# f28p55x_gpio_ctrl_regs register map
Vendor: Texas Instruments
Peripheral module from a debugger description file (folder C2000).
Address unit: 16 bits
Registers are 32-bit, read-write, no defined reset value unless marked. A register's access mark holds for its fields unless they carry their own. Offsets are as the file gives them; lines under a group give offsets from that group; [hi:lo] are bit positions; {n}, {i} and the like mark numbered series; 'fields as' and 'values as' point back to an identical list; <NAME> marks a mode.

## GPIO_CTRL_REGS — GPIO CTRL Registers
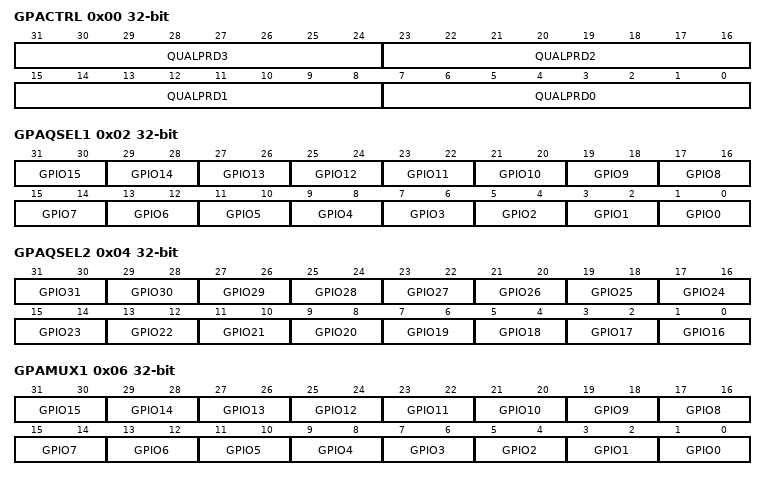
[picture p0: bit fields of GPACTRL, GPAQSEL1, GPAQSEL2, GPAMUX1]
0x00 GPACTRL — GPIO A Qualification Sampling Period Control (GPIO0 to 31)
  [8n+7:8n] QUALPRD{n} (n=0..3) — Qualification sampling period for GPIO{8n} to GPIO{8n+7}
0x02 GPAQSEL1 — GPIO A Qualifier Select 1 Register (GPIO0 to 15)
  [2n+1:2n] GPIO{n} (n=0..15) — Select input qualification type for GPIO{n}
0x04 GPAQSEL2 — GPIO A Qualifier Select 2 Register (GPIO16 to 31)
  [2n-31:2n-32] GPIO{n} (n=16..31) — Select input qualification type for GPIO{n}
0x06 GPAMUX1 — GPIO A Mux 1 Register (GPIO0 to 15)
  [2n+1:2n] GPIO{n} (n=0..15) — Defines pin-muxing selection for GPIO{n}
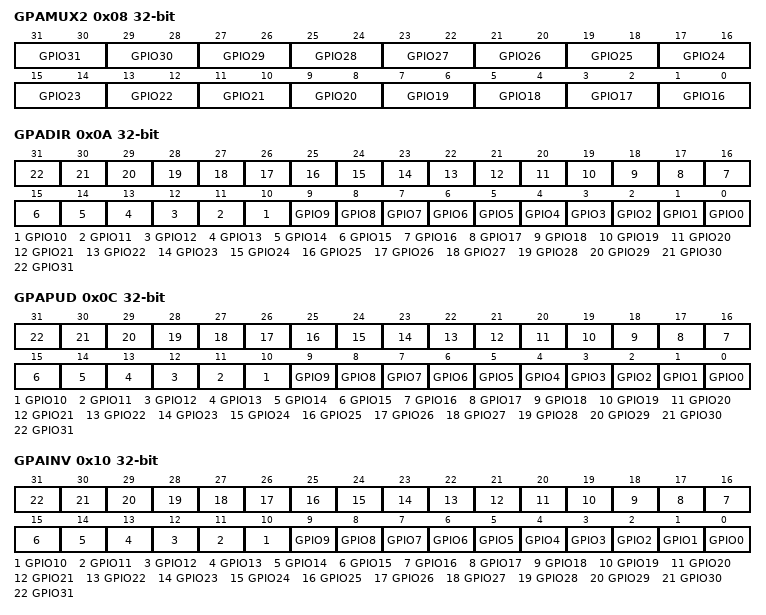
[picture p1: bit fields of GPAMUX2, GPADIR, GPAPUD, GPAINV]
0x08 GPAMUX2 — GPIO A Mux 2 Register (GPIO16 to 31)
  [2n-31:2n-32] GPIO{n} (n=16..31) — Defines pin-muxing selection for GPIO{n}
0x0A GPADIR — GPIO A Direction Register (GPIO0 to 31)
  [n] GPIO{n} (n=0..31) — Defines direction for this pin in GPIO mode
0x0C GPAPUD — GPIO A Pull Up Disable Register (GPIO0 to 31)
  [n] GPIO{n} (n=0..31) — Pull-Up Disable control for this pin
0x10 GPAINV — GPIO A Input Polarity Invert Registers (GPIO0 to 31)
  [n] GPIO{n} (n=0..31) — Input inversion control for this pin
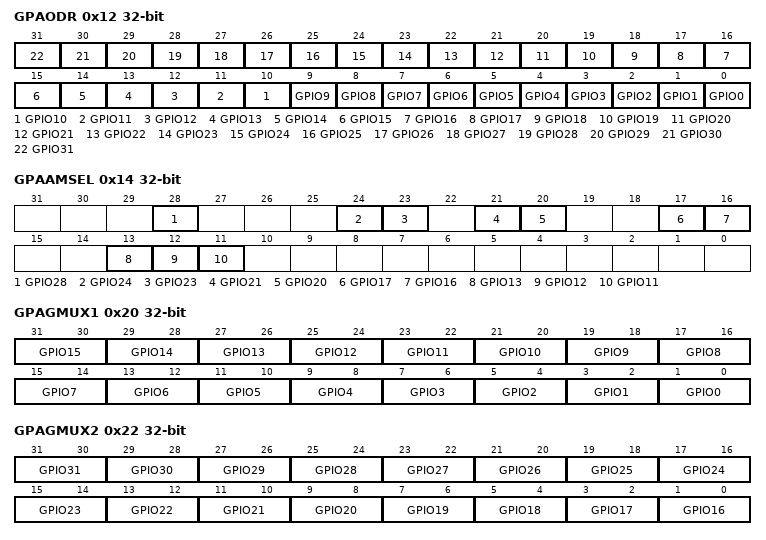
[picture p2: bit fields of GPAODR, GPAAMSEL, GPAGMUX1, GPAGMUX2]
0x12 GPAODR — GPIO A Open Drain Output Register (GPIO0 to GPIO31)
  [n] GPIO{n} (n=0..31) — Outpout Open-Drain control for this pin
0x14 GPAAMSEL — GPIO A Analog Mode Select register (GPIO0 to GPIO31)
  [28] GPIO28 — Analog Mode select for this pin
  [24] GPIO24 — Analog Mode select for this pin
  [23] GPIO23 — Analog Mode select for this pin
  [21] GPIO21 — Analog Mode select for this pin
  [20] GPIO20 — Analog Mode select for this pin
  [17] GPIO17 — Analog Mode select for this pin
  [16] GPIO16 — Analog Mode select for this pin
  [13] GPIO13 — Analog Mode select for this pin
  [12] GPIO12 — Analog Mode select for this pin
  [11] GPIO11 — Analog Mode select for this pin
0x20 GPAGMUX1 — GPIO A Peripheral Group Mux (GPIO0 to 15)
  fields as GPAMUX1
0x22 GPAGMUX2 — GPIO A Peripheral Group Mux (GPIO16 to 31)
  fields as GPAMUX2
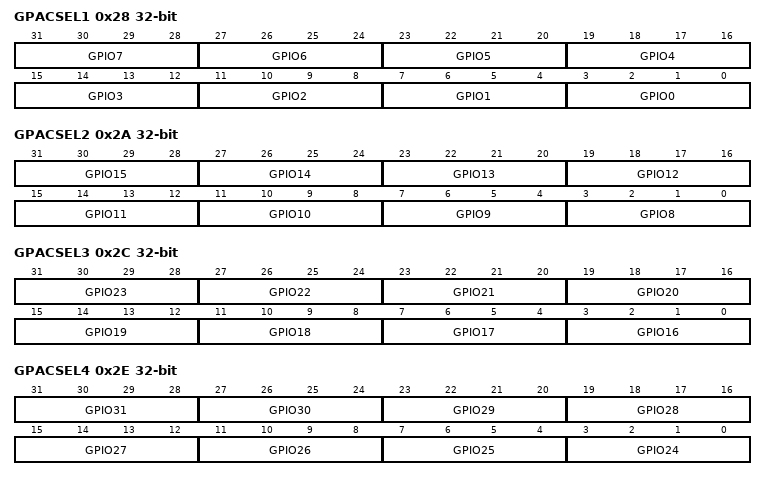
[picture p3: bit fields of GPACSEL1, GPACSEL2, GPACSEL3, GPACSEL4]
0x28 GPACSEL1 — GPIO A Core Select Register (GPIO0 to 7)
  [4n+3:4n] GPIO{n} (n=0..7) — GPIO{n} Controller CPU Select
0x2A GPACSEL2 — GPIO A Core Select Register (GPIO8 to 15)
  [4n-29:4n-32] GPIO{n} (n=8..15) — GPIO{n} Controller CPU Select
0x2C GPACSEL3 — GPIO A Core Select Register (GPIO16 to 23)
  [4n-61:4n-64] GPIO{n} (n=16..23) — GPIO{n} Controller CPU Select
0x2E GPACSEL4 — GPIO A Core Select Register (GPIO24 to 31)
  [4n-93:4n-96] GPIO{n} (n=24..31) — GPIO{n} Controller CPU Select
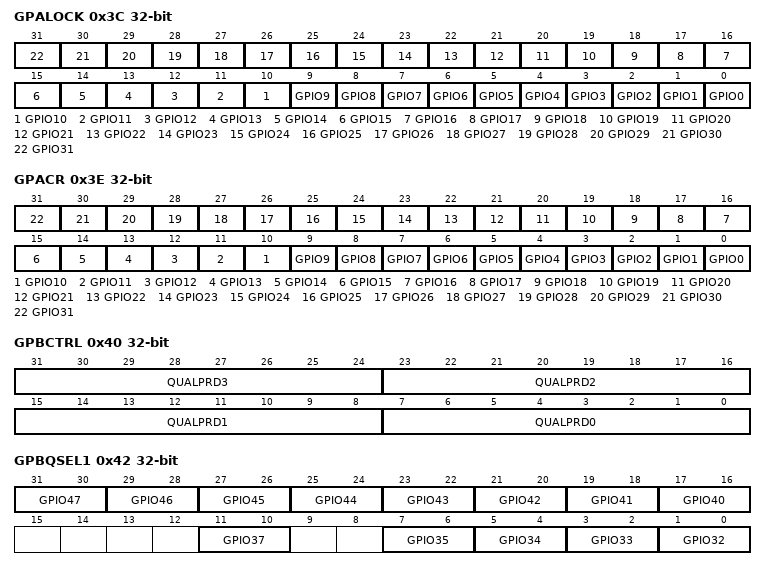
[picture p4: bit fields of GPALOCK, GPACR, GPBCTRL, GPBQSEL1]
0x3C GPALOCK — GPIO A Lock Configuration Register (GPIO0 to 31)
  [n] GPIO{n} (n=0..31) — Configuration Lock bit for this pin
0x3E GPACR — GPIO A Lock Commit Register (GPIO0 to 31)
  [n] GPIO{n} (n=0..31) — Configuration lock commit bit for this pin
0x40 GPBCTRL — GPIO B Qualification Sampling Period Control (GPIO32 to 63)
  [8n+7:8n] QUALPRD{n} (n=0..3) — Qualification sampling period for GPIO{8n+32} to GPIO{8n+39}
0x42 GPBQSEL1 — GPIO B Qualifier Select 1 Register (GPIO32 to 47)
  [2n-63:2n-64] GPIO{n} (n=40..47) — Select input qualification type for GPIO{n}
  [11:10] GPIO37 — Select input qualification type for GPIO37
  [2n-63:2n-64] GPIO{n} (n=32..35) — Select input qualification type for GPIO{n}
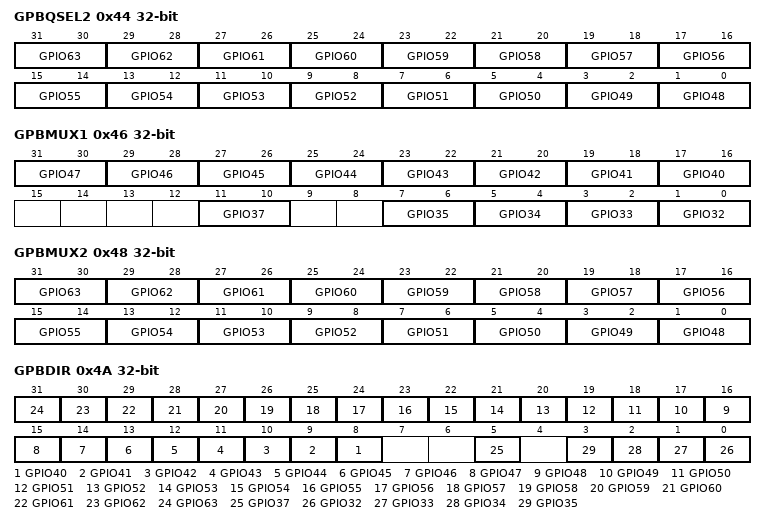
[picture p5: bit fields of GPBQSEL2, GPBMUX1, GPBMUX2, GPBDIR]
0x44 GPBQSEL2 — GPIO B Qualifier Select 2 Register (GPIO48 to 63)
  [2n-95:2n-96] GPIO{n} (n=48..63) — Select input qualification type for GPIO{n}
0x46 GPBMUX1 — GPIO B Mux 1 Register (GPIO32 to 47)
  [2n-63:2n-64] GPIO{n} (n=40..47) — Defines pin-muxing selection for GPIO{n}
  [11:10] GPIO37 — Defines pin-muxing selection for GPIO37
  [2n-63:2n-64] GPIO{n} (n=32..35) — Defines pin-muxing selection for GPIO{n}
0x48 GPBMUX2 — GPIO B Mux 2 Register (GPIO48 to 63)
  [2n-95:2n-96] GPIO{n} (n=48..63) — Defines pin-muxing selection for GPIO{n}
0x4A GPBDIR — GPIO B Direction Register (GPIO32 to 63)
  [n-32] GPIO{n} (n=40..63) — Defines direction for this pin in GPIO mode
  [5] GPIO37 — Defines direction for this pin in GPIO mode
  [n-32] GPIO{n} (n=32..35) — Defines direction for this pin in GPIO mode
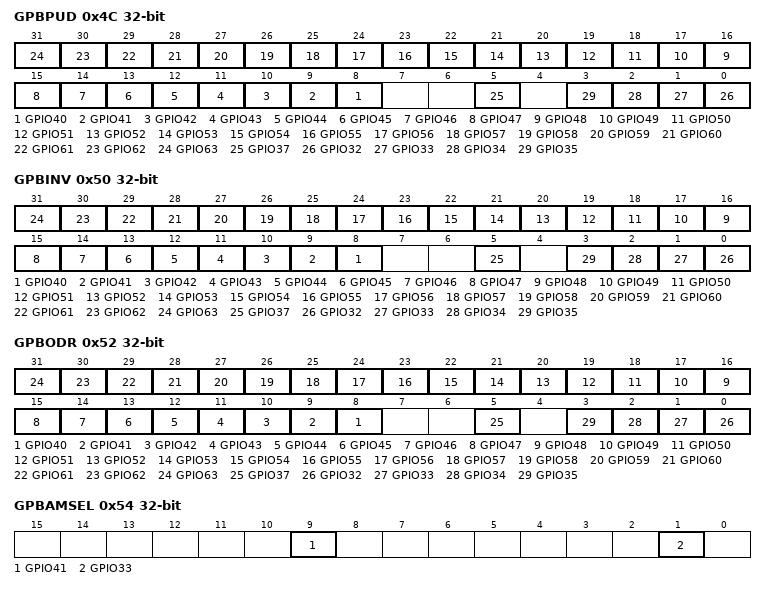
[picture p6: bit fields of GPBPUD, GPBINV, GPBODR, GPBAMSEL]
0x4C GPBPUD — GPIO B Pull Up Disable Register (GPIO32 to 63)
  [n-32] GPIO{n} (n=40..63) — Pull-Up Disable control for this pin
  [5] GPIO37 — Pull-Up Disable control for this pin
  [n-32] GPIO{n} (n=32..35) — Pull-Up Disable control for this pin
0x50 GPBINV — GPIO B Input Polarity Invert Registers (GPIO32 to 63)
  [n-32] GPIO{n} (n=40..63) — Input inversion control for this pin
  [5] GPIO37 — Input inversion control for this pin
  [n-32] GPIO{n} (n=32..35) — Input inversion control for this pin
0x52 GPBODR — GPIO B Open Drain Output Register (GPIO32 to GPIO63)
  [n-32] GPIO{n} (n=40..63) — Outpout Open-Drain control for this pin
  [5] GPIO37 — Outpout Open-Drain control for this pin
  [n-32] GPIO{n} (n=32..35) — Outpout Open-Drain control for this pin
0x54 GPBAMSEL — GPIO B Analog Mode Select register (GPIO32 to GPIO63)
  [9] GPIO41 — Analog Mode select for this pin
  [1] GPIO33 — Analog Mode select for this pin
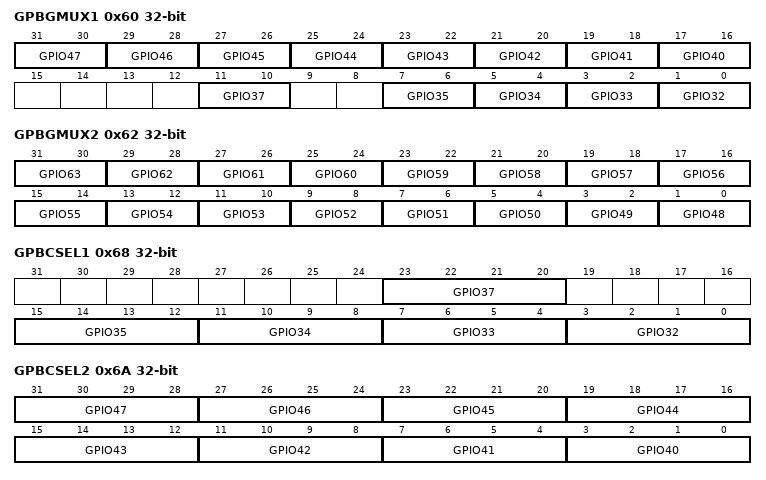
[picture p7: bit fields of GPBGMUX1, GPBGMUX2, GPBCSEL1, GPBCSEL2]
0x60 GPBGMUX1 — GPIO B Peripheral Group Mux (GPIO32 to 47)
  fields as GPBMUX1
0x62 GPBGMUX2 — GPIO B Peripheral Group Mux (GPIO48 to 63)
  fields as GPBMUX2
0x68 GPBCSEL1 — GPIO B Core Select Register (GPIO32 to 39)
  [23:20] GPIO37 — GPIO37 Controller CPU Select
  [4n-125:4n-128] GPIO{n} (n=32..35) — GPIO{n} Controller CPU Select
0x6A GPBCSEL2 — GPIO B Core Select Register (GPIO40 to 47)
  [4n-157:4n-160] GPIO{n} (n=40..47) — GPIO{n} Controller CPU Select
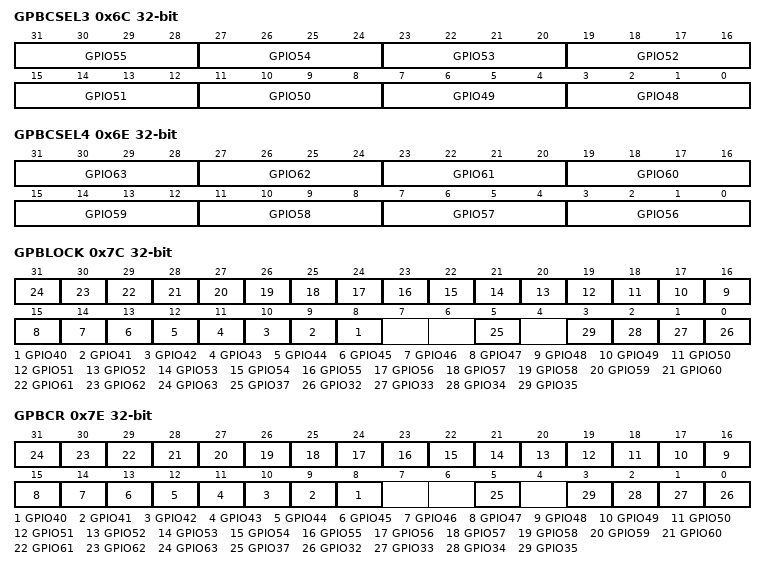
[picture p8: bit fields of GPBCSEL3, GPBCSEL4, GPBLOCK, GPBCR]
0x6C GPBCSEL3 — GPIO B Core Select Register (GPIO48 to 55)
  [4n-189:4n-192] GPIO{n} (n=48..55) — GPIO{n} Controller CPU Select
0x6E GPBCSEL4 — GPIO B Core Select Register (GPIO56 to 63)
  [4n-221:4n-224] GPIO{n} (n=56..63) — GPIO{n} Controller CPU Select
0x7C GPBLOCK — GPIO B Lock Configuration Register (GPIO32 to 63)
  [n-32] GPIO{n} (n=40..63) — Configuration Lock bit for this pin
  [5] GPIO37 — Configuration Lock bit for this pin
  [n-32] GPIO{n} (n=32..35) — Configuration Lock bit for this pin
0x7E GPBCR — GPIO B Lock Commit Register (GPIO32 to 63)
  [n-32] GPIO{n} (n=40..63) — Configuration lock commit bit for this pin
  [5] GPIO37 — Configuration lock commit bit for this pin
  [n-32] GPIO{n} (n=32..35) — Configuration lock commit bit for this pin
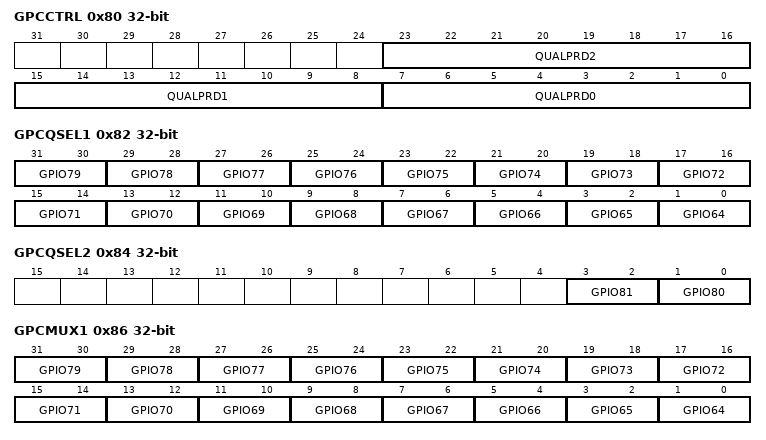
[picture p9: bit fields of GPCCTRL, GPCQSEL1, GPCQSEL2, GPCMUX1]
0x80 GPCCTRL — GPIO C Qualification Sampling Period Control (GPIO64 to 95)
  [23:16] QUALPRD2 — Qualification sampling period for GPIO80 to GPIO87
  [15:8] QUALPRD1 — Qualification sampling period for GPIO72 to GPIO79
  [7:0] QUALPRD0 — Qualification sampling period for GPIO64 to GPIO71
0x82 GPCQSEL1 — GPIO C Qualifier Select 1 Register (GPIO64 to 79)
  [2n-127:2n-128] GPIO{n} (n=64..79) — Select input qualification type for GPIO{n}
0x84 GPCQSEL2 — GPIO C Qualifier Select 2 Register (GPIO80 to 95)
  [3:2] GPIO81 — Select input qualification type for GPIO81
  [1:0] GPIO80 — Select input qualification type for GPIO80
0x86 GPCMUX1 — GPIO C Mux 1 Register (GPIO64 to 79)
  [2n-127:2n-128] GPIO{n} (n=64..79) — Defines pin-muxing selection for GPIO{n}
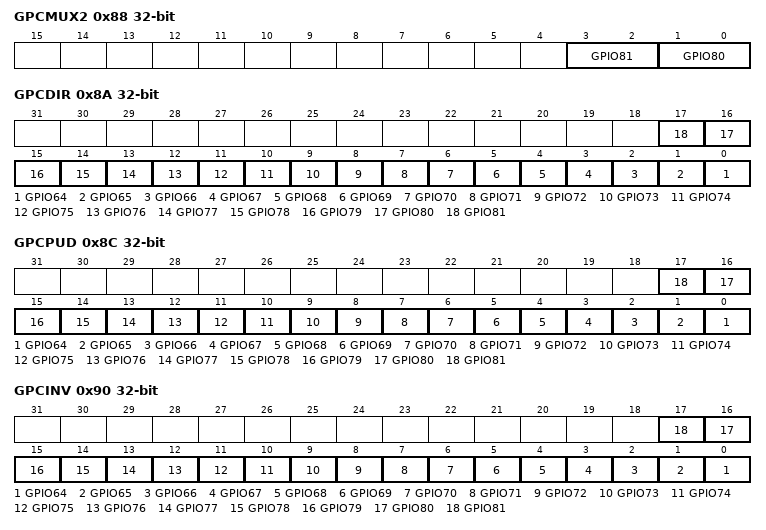
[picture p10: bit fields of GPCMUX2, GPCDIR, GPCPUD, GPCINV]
0x88 GPCMUX2 — GPIO C Mux 2 Register (GPIO80 to 95)
  [3:2] GPIO81 — Defines pin-muxing selection for GPIO81
  [1:0] GPIO80 — Defines pin-muxing selection for GPIO80
0x8A GPCDIR — GPIO C Direction Register (GPIO64 to 95)
  [n-64] GPIO{n} (n=64..81) — Defines direction for this pin in GPIO mode
0x8C GPCPUD — GPIO C Pull Up Disable Register (GPIO64 to 95)
  [n-64] GPIO{n} (n=64..81) — Pull-Up Disable control for this pin
0x90 GPCINV — GPIO C Input Polarity Invert Registers (GPIO64 to 95)
  [n-64] GPIO{n} (n=64..81) — Input inversion control for this pin
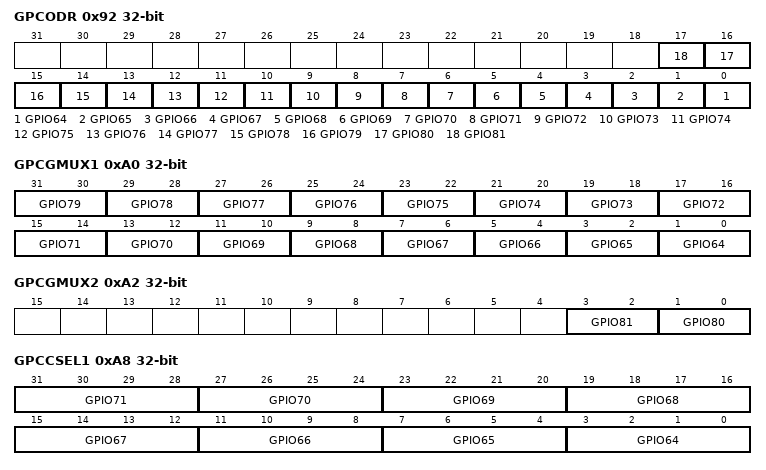
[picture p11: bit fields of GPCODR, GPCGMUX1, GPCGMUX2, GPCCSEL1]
0x92 GPCODR — GPIO C Open Drain Output Register (GPIO64 to GPIO95)
  [n-64] GPIO{n} (n=64..81) — Outpout Open-Drain control for this pin
0x94 GPCAMSEL access not given — GPIO C Analog Mode Select register (GPIO64 to GPIO95)
0xA0 GPCGMUX1 — GPIO C Peripheral Group Mux (GPIO64 to 79)
  fields as GPCMUX1
0xA2 GPCGMUX2 — GPIO C Peripheral Group Mux (GPIO80 to 95)
  fields as GPCMUX2
0xA8 GPCCSEL1 — GPIO C Core Select Register (GPIO64 to 71)
  [4n-253:4n-256] GPIO{n} (n=64..71) — GPIO{n} Controller CPU Select
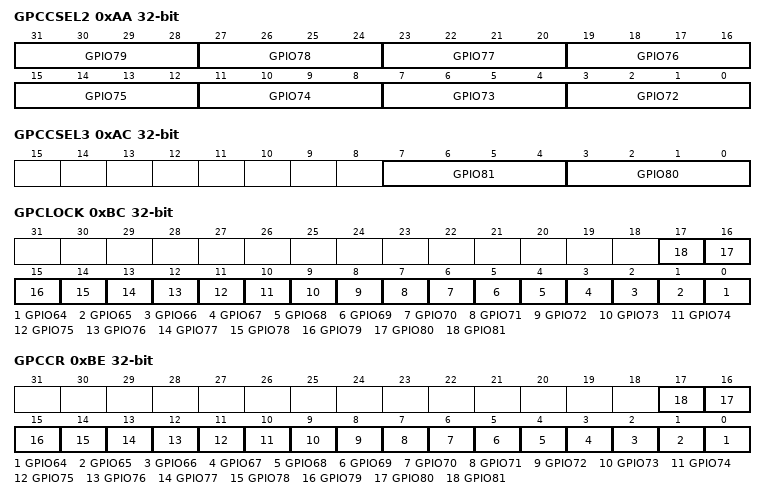
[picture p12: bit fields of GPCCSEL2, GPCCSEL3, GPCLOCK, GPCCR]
0xAA GPCCSEL2 — GPIO C Core Select Register (GPIO72 to 79)
  [4n-285:4n-288] GPIO{n} (n=72..79) — GPIO{n} Controller CPU Select
0xAC GPCCSEL3 — GPIO C Core Select Register (GPIO80 to 87)
  [7:4] GPIO81 — GPIO81 Controller CPU Select
  [3:0] GPIO80 — GPIO80 Controller CPU Select
0xBC GPCLOCK — GPIO C Lock Configuration Register (GPIO64 to 95)
  [n-64] GPIO{n} (n=64..81) — Configuration Lock bit for this pin
0xBE GPCCR — GPIO C Lock Commit Register (GPIO64 to 95)
  [n-64] GPIO{n} (n=64..81) — Configuration lock commit bit for this pin
0x180 GPGCTRL — GPIO G Qualification Sampling Period Control (GPIO192 to 223)
  [23:16] QUALPRD2 — Qualification sampling period for GPIO208 to GPIO215
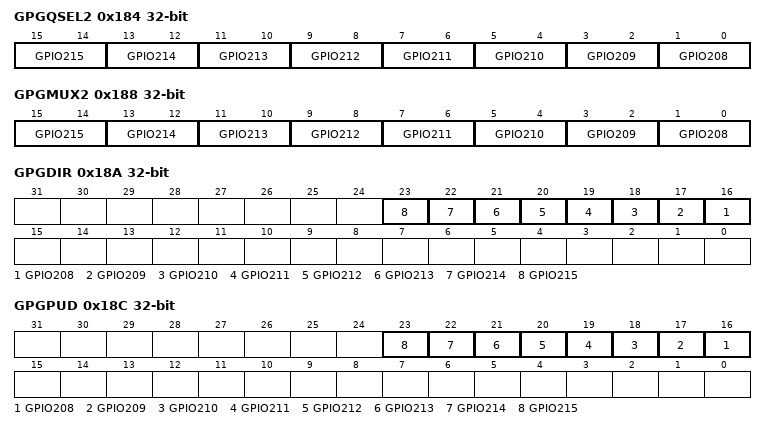
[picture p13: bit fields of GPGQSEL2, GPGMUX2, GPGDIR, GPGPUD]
0x184 GPGQSEL2 — GPIO G Qualifier Select 2 Register (GPIO208 to 223)
  [2n-415:2n-416] GPIO{n} (n=208..215) — Select input qualification type for GPIO{n}
0x188 GPGMUX2 — GPIO G Mux 2 Register (GPIO208 to 223)
  [2n-415:2n-416] GPIO{n} (n=208..215) — Defines pin-muxing selection for GPIO{n}
0x18A GPGDIR — GPIO G Direction Register (GPIO192 to 223)
  [n-192] GPIO{n} (n=208..215) — Defines direction for this pin in GPIO mode
0x18C GPGPUD — GPIO G Pull Up Disable Register (GPIO192 to 223)
  [n-192] GPIO{n} (n=208..215) — Pull-Up Disable control for this pin
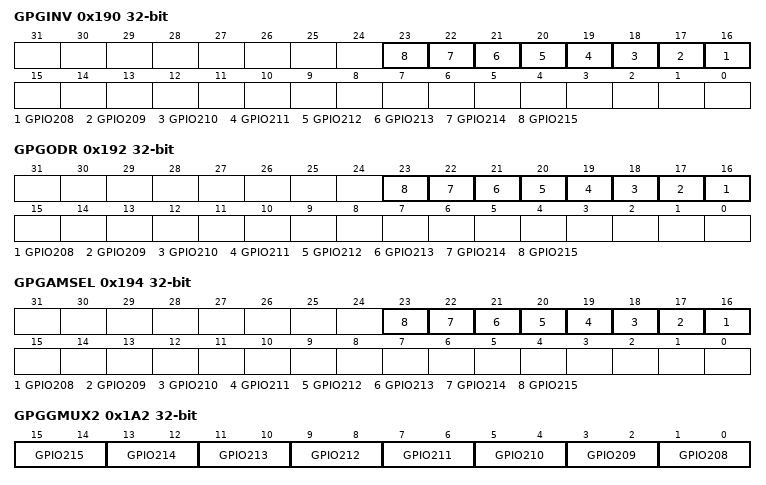
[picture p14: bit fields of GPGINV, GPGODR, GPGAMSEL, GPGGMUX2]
0x190 GPGINV — GPIO G Input Polarity Invert Registers (GPIO192 to 223)
  [n-192] GPIO{n} (n=208..215) — Input inversion control for this pin
0x192 GPGODR — GPIO G Open Drain Output Register (GPIO192 to 223)
  [n-192] GPIO{n} (n=208..215) — Outpout Open-Drain control for this pin
0x194 GPGAMSEL — GPIO G Analog Mode Select register (GPIO192 to 223)
  [n-192] GPIO{n} (n=208..215) — Analog Mode select for this pin
0x1A2 GPGGMUX2 — GPIO G Peripheral Group Mux (GPIO208 to 223)
  fields as GPGMUX2
0x1AC GPGCSEL3 — GPIO G Core Select Register (GPIO208 to 215)
  [4n-829:4n-832] GPIO{n} (n=208..215) — GPIO{n} Controller CPU Select
0x1BC GPGLOCK — GPIO G Lock Configuration Register (GPIO192 to 223)
  [n-192] GPIO{n} (n=208..215) — Configuration Lock bit for this pin
0x1BE GPGCR — GPIO G Lock Commit Register (GPIO192 to 223)
  [n-192] GPIO{n} (n=208..215) — Configuration lock commit bit for this pin
0x1C0 GPHCTRL — GPIO H Qualification Sampling Period Control (GPIO224 to 255)
  [8n+7:8n] QUALPRD{n} (n=0..3) — Qualification sampling period for GPIO{8n+224} to GPIO{8n+231}
0x1C2 GPHQSEL1 — GPIO H Qualifier Select 1 Register (GPIO224 to 239)
  [2n-447:2n-448] GPIO{n} (n=224..239) — Select input qualification type for this GPIO Pin
0x1C4 GPHQSEL2 — GPIO H Qualifier Select 2 Register (GPIO240 to 255)
  [27:26] GPIO253 — Select input qualification type for this GPIO Pin
  [25:24] GPIO252 — Select input qualification type for this GPIO Pin
  [23:22] GPIO251 — Select input qualification type for this GPIO Pin
  [19:18] GPIO249 — Select input qualification type for this GPIO Pin
  [17:16] GPIO248 — Select input qualification type for this GPIO Pin
  [15:14] GPIO247 — Select input qualification type for this GPIO Pin
  [11:10] GPIO245 — Select input qualification type for this GPIO Pin
  [9:8] GPIO244 — Select input qualification type for this GPIO Pin
  [5:4] GPIO242 — Select input qualification type for this GPIO Pin
  [3:2] GPIO241 — Select input qualification type for this GPIO Pin
  [1:0] GPIO240 — Select input qualification type for this GPIO Pin
0x1C6 GPHMUX1 — GPIO H Mux 1 Register (GPIO224 to 239)
  [2n-447:2n-448] GPIO{n} (n=224..239) — Defines pin-muxing selection for GPIO{n}
0x1C8 GPHMUX2 — GPIO H Mux 2 Register (GPIO240 to 255)
  [27:26] GPIO253 — Defines pin-muxing selection for GPIO253
  [25:24] GPIO252 — Defines pin-muxing selection for GPIO252
  [23:22] GPIO251 — Defines pin-muxing selection for GPIO251
  [19:18] GPIO249 — Defines pin-muxing selection for GPIO249
  [17:16] GPIO248 — Defines pin-muxing selection for GPIO248
  [15:14] GPIO247 — Defines pin-muxing selection for GPIO247
  [11:10] GPIO245 — Defines pin-muxing selection for GPIO245
  [9:8] GPIO244 — Defines pin-muxing selection for GPIO244
  [5:4] GPIO242 — Defines pin-muxing selection for GPIO242
  [3:2] GPIO241 — Defines pin-muxing selection for GPIO241
  [1:0] GPIO240 — Defines pin-muxing selection for GPIO240
0x1CA GPHDIR — GPIO H Direction Register (GPIO224 to 255)
  [29] GPIO253 — Defines direction for this pin in GPIO mode
  [28] GPIO252 — Defines direction for this pin in GPIO mode
  [27] GPIO251 — Defines direction for this pin in GPIO mode
  [25] GPIO249 — Defines direction for this pin in GPIO mode
  [24] GPIO248 — Defines direction for this pin in GPIO mode
  [23] GPIO247 — Defines direction for this pin in GPIO mode
  [21] GPIO245 — Defines direction for this pin in GPIO mode
  [20] GPIO244 — Defines direction for this pin in GPIO mode
  [n-224] GPIO{n} (n=224..242) — Defines direction for this pin in GPIO mode
0x1CC GPHPUD — GPIO H Pull Up Disable Register (GPIO224 to 255)
  [29] GPIO253 — Pull-Up Disable control for this pin
  [28] GPIO252 — Pull-Up Disable control for this pin
  [27] GPIO251 — Pull-Up Disable control for this pin
  [25] GPIO249 — Pull-Up Disable control for this pin
  [24] GPIO248 — Pull-Up Disable control for this pin
  [23] GPIO247 — Pull-Up Disable control for this pin
  [21] GPIO245 — Pull-Up Disable control for this pin
  [20] GPIO244 — Pull-Up Disable control for this pin
  [n-224] GPIO{n} (n=224..242) — Pull-Up Disable control for this pin
0x1D0 GPHINV — GPIO H Input Polarity Invert Registers (GPIO224 to 255)
  [29] GPIO253 — Input inversion control for this pin
  [28] GPIO252 — Input inversion control for this pin
  [27] GPIO251 — Input inversion control for this pin
  [25] GPIO249 — Input inversion control for this pin
  [24] GPIO248 — Input inversion control for this pin
  [23] GPIO247 — Input inversion control for this pin
  [21] GPIO245 — Input inversion control for this pin
  [20] GPIO244 — Input inversion control for this pin
  [n-224] GPIO{n} (n=224..242) — Input inversion control for this pin
0x1D2 GPHODR — GPIO H Open Drain Output Register (GPIO224 to GPIO255)
  [29] GPIO253 — Outpout Open-Drain control for this pin
  [28] GPIO252 — Outpout Open-Drain control for this pin
  [27] GPIO251 — Outpout Open-Drain control for this pin
  [25] GPIO249 — Outpout Open-Drain control for this pin
  [24] GPIO248 — Outpout Open-Drain control for this pin
  [23] GPIO247 — Outpout Open-Drain control for this pin
  [21] GPIO245 — Outpout Open-Drain control for this pin
  [20] GPIO244 — Outpout Open-Drain control for this pin
  [n-224] GPIO{n} (n=224..242) — Outpout Open-Drain control for this pin
0x1D4 GPHAMSEL — GPIO H Analog Mode Select register (GPIO224 to GPIO255)
  [29] GPIO253 — Analog Mode select for this pin
  [28] GPIO252 — Analog Mode select for this pin
  [27] GPIO251 — Analog Mode select for this pin
  [25] GPIO249 — Analog Mode select for this pin
  [24] GPIO248 — Analog Mode select for this pin
  [23] GPIO247 — Analog Mode select for this pin
  [21] GPIO245 — Analog Mode select for this pin
  [20] GPIO244 — Analog Mode select for this pin
  [n-224] GPIO{n} (n=224..242) — Analog Mode select for this pin
0x1E0 GPHGMUX1 — GPIO H Peripheral Group Mux (GPIO224 to 239)
  fields as GPHMUX1
0x1E2 GPHGMUX2 — GPIO H Peripheral Group Mux (GPIO240 to 255)
  fields as GPHMUX2
0x1E8 GPHCSEL1 — GPIO H Core Select Register (GPIO224 to 231)
  [4n-893:4n-896] GPIO{n} (n=224..231) — GPIO{n} Controller CPU Select
0x1EA GPHCSEL2 — GPIO H Core Select Register (GPIO232 to 239)
  [4n-925:4n-928] GPIO{n} (n=232..239) — GPIO{n} Controller CPU Select
0x1EC GPHCSEL3 — GPIO H Core Select Register (GPIO240 to 247)
  [31:28] GPIO247 — GPIO247 Controller CPU Select
  [23:20] GPIO245 — GPIO245 Controller CPU Select
  [19:16] GPIO244 — GPIO244 Controller CPU Select
  [11:8] GPIO242 — GPIO242 Controller CPU Select
  [7:4] GPIO241 — GPIO241 Controller CPU Select
  [3:0] GPIO240 — GPIO240 Controller CPU Select
0x1EE GPHCSEL4 — GPIO H Core Select Register (GPIO248 to 255)
  [23:20] GPIO253 — GPIO253 Controller CPU Select
  [19:16] GPIO252 — GPIO252 Controller CPU Select
  [15:12] GPIO251 — GPIO251 Controller CPU Select
  [7:4] GPIO249 — GPIO249 Controller CPU Select
  [3:0] GPIO248 — GPIO248 Controller CPU Select
0x1FC GPHLOCK — GPIO H Lock Configuration Register (GPIO224 to 255)
  [29] GPIO253 — Configuration Lock bit for this pin
  [28] GPIO252 — Configuration Lock bit for this pin
  [27] GPIO251 — Configuration Lock bit for this pin
  [25] GPIO249 — Configuration Lock bit for this pin
  [24] GPIO248 — Configuration Lock bit for this pin
  [23] GPIO247 — Configuration Lock bit for this pin
  [21] GPIO245 — Configuration Lock bit for this pin
  [20] GPIO244 — Configuration Lock bit for this pin
  [n-224] GPIO{n} (n=224..242) — Configuration Lock bit for this pin
0x1FE GPHCR — GPIO H Lock Commit Register (GPIO224 to 255)
  [29] GPIO253 — Configuration lock commit bit for this pin
  [28] GPIO252 — Configuration lock commit bit for this pin
  [27] GPIO251 — Configuration lock commit bit for this pin
  [25] GPIO249 — Configuration lock commit bit for this pin
  [24] GPIO248 — Configuration lock commit bit for this pin
  [23] GPIO247 — Configuration lock commit bit for this pin
  [21] GPIO245 — Configuration lock commit bit for this pin
  [20] GPIO244 — Configuration lock commit bit for this pin
  [n-224] GPIO{n} (n=224..242) — Configuration lock commit bit for this pin
